AUTOSAR XML (schema 4-2-1)
package /VehicleProject
  system System
package /Diagnostics
  diagnostic service table DS_MyECU: diagnostic-connections=DC_0xE001_oMyECU_oCAN, ecu-instance=MyECU
  diagnostic connection DC_0xE001_oMyECU_oCAN: functional-request=msg_diag_RequestGlobal_oTN_0x00E0_Tester, physical-request=msg_diag_Request_MyECU_oTN_0x0001_MyECU, response=msg_diag_Response_MyECU_oTN_0x0001_MyECU
package /NM
  nm config NmConfig: can-nm-cluster-coupling=coupled-cluster=CAN
    can nm cluster CAN: communication-cluster=CAN, nm-channel-id=0, nm-cbv-position=0, nm-msg-cycle-time=0.1, nm-network-timeout=1, nm-nid-position=1, nm-repeat-message-time=0.4, nm-user-data-length=6, nm-wait-bus-sleep-time=0.75
      can nm node MyECU: controller=CT_CAN, nm-if-ecu=MyECU_CAN, nm-node-id=0, rx-nm-pdu=[msg_nm_OtherECU_oCAN, msg_nm_RearECU_oCAN], tx-nm-pdu=msg_nm_MyECU_oCAN, nm-msg-cycle-offset=0, nm-msg-reduced-time=0.05, nm-range-config={lower-can-id=1024, upper-can-id=1087}
      can nm node OtherECU: nm-if-ecu=OtherECU_CAN, nm-node-id=2, rx-nm-pdu=[msg_nm_MyECU_oCAN, msg_nm_RearECU_oCAN], tx-nm-pdu=msg_nm_OtherECU_oCAN, nm-msg-cycle-offset=0, nm-msg-reduced-time=0.05, nm-range-config={lower-can-id=1024, upper-can-id=1087}
      can nm node RearECU: nm-if-ecu=RearECU_CAN, nm-node-id=1, rx-nm-pdu=[msg_nm_MyECU_oCAN, msg_nm_OtherECU_oCAN], tx-nm-pdu=msg_nm_RearECU_oCAN, nm-msg-cycle-offset=0, nm-msg-reduced-time=0.05, nm-range-config={lower-can-id=1024, upper-can-id=1087}
    nm-if-ecus:
      nm ecu MyECU_CAN: ecu-instance=MyECU, nm-node-id-enabled=true, nm-user-data-enabled=true
      nm ecu OtherECU_CAN: nm-node-id-enabled=true, nm-user-data-enabled=true
      nm ecu RearECU_CAN: nm-node-id-enabled=true, nm-user-data-enabled=true
package /TP
  can tp config CAN: communication-cluster=CAN, can-tp-ecu{cycle-time-main-function=0.005, ecu-instance=MyECU}
    can tp address TA_0x0000: tp-address=0
    can tp address TA_0x0001: tp-address=1
    can tp address TA_0x00E0: tp-address=224
    can tp channel TPCH: channel-id=0, channel-mode=FULL-DUPLEX-MODE
    can-tp-connection addressing-format=STANDARD, can-tp-channel=TPCH, data-pdu=msg_diag_RequestGlobal_Tp_oCAN, multicast=TA_0x0000, receiver=TN_MyECU, ta-type=FUNCTIONAL, tp-sdu=msg_diag_RequestGlobal_oCAN, transmitter=TN_0x00E0_Tester:
      ident msg_diag_RequestGlobal_oTN_0x00E0_Tester
    can-tp-connection addressing-format=STANDARD, can-tp-channel=TPCH, data-pdu=msg_diag_Request_MyECU_Tp_oCAN, flow-control-pdu=msg_diag_Response_MyECU_Tp_oCAN, receiver=TN_0x0001_MyECU, ta-type=PHYSICAL, tp-sdu=msg_diag_Request_MyECU_oCAN, transmitter=TN_0x00E0_Tester:
      ident msg_diag_Request_MyECU_oTN_0x0001_MyECU
    can-tp-connection addressing-format=STANDARD, can-tp-channel=TPCH, data-pdu=msg_diag_Response_MyECU_Tp_oCAN, flow-control-pdu=msg_diag_Request_MyECU_Tp_oCAN, receiver=TN_0x00E0_Tester, ta-type=PHYSICAL, tp-sdu=msg_diag_Response_MyECU_oCAN, transmitter=TN_0x0001_MyECU:
      ident msg_diag_Response_MyECU_oTN_0x0001_MyECU
    can tp node TN_0x0001_MyECU: connector=CN_CAN, tp-address=TA_0x0001
    can tp node TN_0x00E0_Tester: tp-address=TA_0x00E0
    can tp node TN_MyECU: connector=CN_CAN
package /Cluster
  can cluster CAN: baudrate=500000, protocol-name=CAN
    can physical channel CHNL: comm-connectors=CN_CAN
      frame GlobalTimeMaster_oCAN: id 0x380, to MyECU, frame-length=8, can-addressing-mode=STANDARD
        user defined pdu GlobalTimeMaster_oCAN: length=8
      frame msg_diag_Request_MyECU_oCAN: id 0x610, to MyECU, frame-length=8, can-addressing-mode=STANDARD
        n pdu msg_diag_Request_MyECU_Tp_oCAN: length=8
      frame msg_diag_Request_MyECU_Slave3_oCAN: id 0x611, to MyECU, frame-length=8, can-addressing-mode=STANDARD
        user defined pdu msg_diag_Request_MyECU_Slave3_oCAN: length=8
      frame msg_diag_RequestGlobal_oCAN: id 0x614, to MyECU, frame-length=8, can-addressing-mode=STANDARD
        n pdu msg_diag_RequestGlobal_Tp_oCAN: length=8
      frame msg_diag_Response_MyECU_oCAN: id 0x612, from MyECU, frame-length=8, can-addressing-mode=STANDARD
        n pdu msg_diag_Response_MyECU_Tp_oCAN: length=8
      frame msg_diag_Response_MyECU_Slave3_oCAN: id 0x613, from MyECU, frame-length=8, can-addressing-mode=STANDARD
        user defined pdu msg_diag_Response_MyECU_Slave3_oCAN: length=8
      frame msg_diag_Uudt_Response_MyECU_oCAN: id 0x616, from MyECU, frame-length=8, can-addressing-mode=STANDARD
        dcm i pdu msg_diag_Uudt_Response_MyECU_oCAN: length=8, diag-pdu-type=DIAG-RESPONSE
      frame msg_nm_MyECU_oCAN: id 0x400, from MyECU, frame-length=8, can-addressing-mode=STANDARD
        nm pdu msg_nm_MyECU_oCAN: length=8, unused-bit-pattern=0
          signal NmUd_MyECU_16bit_omsg_nm_MyECU_oCAN: start 16, 16 bit, little-endian, init-value=0, base-type=uint16, compu-method=CM_NmUd_MyECU_16bit, transfer-property=PENDING
          signal NmUd_MyECU_32bit_omsg_nm_MyECU_oCAN: start 32, 32 bit, little-endian, init-value=0, base-type=uint32, compu-method=CM_NmUd_MyECU_32bit, transfer-property=PENDING
      frame msg_nm_OtherECU_oCAN: id 0x402, to MyECU, frame-length=8, can-addressing-mode=STANDARD
        nm pdu msg_nm_OtherECU_oCAN: length=8, unused-bit-pattern=0
      frame msg_nm_RearECU_oCAN: id 0x401, to MyECU, frame-length=8, can-addressing-mode=STANDARD
        nm pdu msg_nm_RearECU_oCAN: length=8, unused-bit-pattern=0
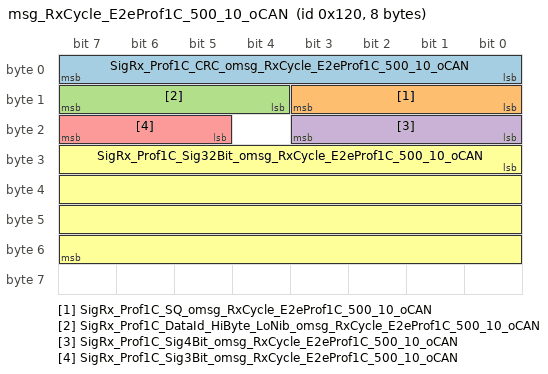
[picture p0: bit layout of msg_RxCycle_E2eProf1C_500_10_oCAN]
      frame msg_RxCycle_E2eProf1C_500_10_oCAN: id 0x120, to MyECU, frame-length=8, can-addressing-mode=STANDARD
        pdu msg_RxCycle_E2eProf1C_500_10_oCAN: length=8, minimum-delay=0, transmission-mode-false-timing=cyclic-timing={time-offset=0.01, time-period=0.5}, transmission-mode-true-timing=cyclic-timing={time-offset=0.01, time-period=0.5}, unused-bit-pattern=0
          signal SigRx_Prof1C_CRC_omsg_RxCycle_E2eProf1C_500_10_oCAN: start 0, 8 bit, little-endian, init-value=0, base-type=uint8, compu-method=CM_SigRx_Prof1C_CRC, transfer-property=PENDING, to MyECU
          signal SigRx_Prof1C_SQ_omsg_RxCycle_E2eProf1C_500_10_oCAN: start 8, 4 bit, little-endian, init-value=0, base-type=uint8, compu-method=CM_SigRx_Prof1C_SQ, transfer-property=PENDING, to MyECU
          signal SigRx_Prof1C_DataId_HiByte_LoNib_omsg_RxCycle_E2eProf1C_500_10_oCAN: start 12, 4 bit, little-endian, init-value=0, base-type=uint8, compu-method=CM_SigRx_Prof1C_DataId_HiByte_LoNib, transfer-property=PENDING, to MyECU
          signal SigRx_Prof1C_Sig4Bit_omsg_RxCycle_E2eProf1C_500_10_oCAN: start 16, 4 bit, little-endian, init-value=0, base-type=uint8, compu-method=CM_SigRx_Prof1C_Sig4Bit, transfer-property=PENDING, to MyECU
          signal SigRx_Prof1C_Sig3Bit_omsg_RxCycle_E2eProf1C_500_10_oCAN: start 21, 3 bit, little-endian, init-value=0, base-type=uint8, compu-method=CM_SigRx_Prof1C_Sig3Bit, transfer-property=PENDING, to MyECU
          signal SigRx_Prof1C_Sig32Bit_omsg_RxCycle_E2eProf1C_500_10_oCAN: start 24, 32 bit, little-endian, init-value=0, base-type=uint32, compu-method=CM_SigRx_Prof1C_Sig32Bit, transfer-property=PENDING, to MyECU
          mapping SG_RgRx_Prof1C_RxCycle: i-signal-group=SG_RgRx_Prof1C_RxCycle_omsg_RxCycle_E2eProf1C_500_10_oCAN, transfer-property=PENDING
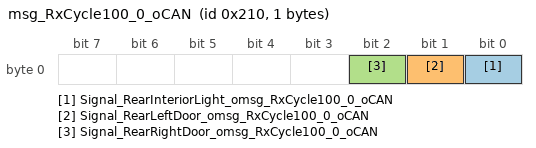
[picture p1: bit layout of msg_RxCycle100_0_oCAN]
      frame msg_RxCycle100_0_oCAN: id 0x210, to MyECU, frame-length=1, can-addressing-mode=STANDARD
        pdu msg_RxCycle100_0_oCAN: length=1, minimum-delay=0, transmission-mode-false-timing=cyclic-timing={time-offset=0, time-period=0.1}, transmission-mode-true-timing=cyclic-timing={time-offset=0, time-period=0.1}, unused-bit-pattern=0
          signal Signal_RearInteriorLight_omsg_RxCycle100_0_oCAN: start 0, 1 bit, little-endian, init-value=0, base-type=boolean, compu-method=CM_Signal_RearInteriorLight, transfer-property=PENDING, to MyECU
          signal Signal_RearLeftDoor_omsg_RxCycle100_0_oCAN: start 1, 1 bit, little-endian, init-value=0, base-type=boolean, compu-method=CM_Signal_RearLeftDoor, transfer-property=PENDING, to MyECU
          signal Signal_RearRightDoor_omsg_RxCycle100_0_oCAN: start 2, 1 bit, little-endian, init-value=0, base-type=boolean, compu-method=CM_Signal_RearRightDoor, transfer-property=PENDING, to MyECU
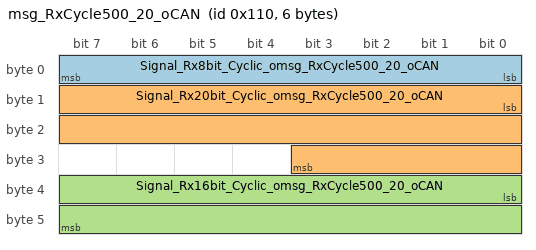
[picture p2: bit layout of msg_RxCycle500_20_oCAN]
      frame msg_RxCycle500_20_oCAN: id 0x110, to MyECU, frame-length=6, can-addressing-mode=STANDARD
        pdu msg_RxCycle500_20_oCAN: length=6, minimum-delay=0, transmission-mode-false-timing=cyclic-timing={time-offset=0.02, time-period=0.5}, transmission-mode-true-timing=cyclic-timing={time-offset=0.02, time-period=0.5}, unused-bit-pattern=0
          signal Signal_Rx8bit_Cyclic_omsg_RxCycle500_20_oCAN: start 0, 8 bit, little-endian, init-value=15, base-type=uint8, compu-method=CM_Signal_Rx8bit_Cyclic, transfer-property=PENDING, to MyECU
          signal Signal_Rx20bit_Cyclic_omsg_RxCycle500_20_oCAN: start 8, 20 bit, little-endian, init-value=1, base-type=uint32, compu-method=CM_Signal_Rx20bit_Cyclic, transfer-property=PENDING, to MyECU
          signal Signal_Rx16bit_Cyclic_omsg_RxCycle500_20_oCAN: start 32, 16 bit, little-endian, init-value=32768, base-type=uint16, compu-method=CM_Signal_Rx16bit_Cyclic, transfer-property=PENDING, to MyECU
      frame msg_RxEvent_20_oCAN: id 0x310, to MyECU, frame-length=4, can-addressing-mode=STANDARD
        pdu msg_RxEvent_20_oCAN: length=4, minimum-delay=0, transmission-mode-false-timing=event-controlled-timing={number-of-repetitions=0, repetition-period=0}, transmission-mode-true-timing=event-controlled-timing={number-of-repetitions=0, repetition-period=0}, unused-bit-pattern=0
          signal Signal_Rx11bit_OnWrite_omsg_RxEvent_20_oCAN: start 0, 11 bit, little-endian, init-value=50, base-type=uint16, compu-method=CM_Signal_Rx11bit_OnWrite, transfer-property=TRIGGERED-WITHOUT-REPETITION, to MyECU
          signal Signal_Rx15bit_OnWrite_omsg_RxEvent_20_oCAN: start 12, 15 bit, little-endian, init-value=25, base-type=uint16, compu-method=CM_Signal_Rx15bit_OnWrite, transfer-property=TRIGGERED-WITHOUT-REPETITION, to MyECU
      frame msg_StartAppl_Rx_MyECU_oCAN: id 0x501, to MyECU, frame-length=8, can-addressing-mode=STANDARD
        pdu msg_StartAppl_Rx_MyECU_oCAN: length=8, minimum-delay=0, transmission-mode-false-timing=cyclic-timing={time-offset=0, time-period=0.05}, transmission-mode-true-timing=cyclic-timing={time-offset=0, time-period=0.05}, unused-bit-pattern=0
          signal Signal_StartAppl_RxCtrl_MyECU_omsg_StartAppl_Rx_MyECU_oCAN: start 0, 8 bit, little-endian, init-value=0, base-type=uint8, compu-method=CM_Signal_StartAppl_RxCtrl_MyECU, transfer-property=PENDING, to MyECU
          signal Signal_StartAppl_RxData_MyECU_omsg_StartAppl_Rx_MyECU_oCAN: start 8, 8 bit, little-endian, init-value=0, base-type=uint8, compu-method=CM_Signal_StartAppl_RxData_MyECU, transfer-property=PENDING, to MyECU
      frame msg_StartAppl_Tx_MyECU_oCAN: id 0x500, from MyECU, frame-length=8, can-addressing-mode=STANDARD
        pdu msg_StartAppl_Tx_MyECU_oCAN: length=8, minimum-delay=0, transmission-mode-false-timing=cyclic-timing={time-offset=0, time-period=0.05}, transmission-mode-true-timing=cyclic-timing={time-offset=0, time-period=0.05}, unused-bit-pattern=0
          signal Signal_StartAppl_TxCtrl_MyECU_omsg_StartAppl_Tx_MyECU_oCAN: start 0, 8 bit, little-endian, init-value=0, base-type=uint8, compu-method=CM_Signal_StartAppl_TxCtrl_MyECU, transfer-property=PENDING
          signal Signal_StartAppl_TxData_MyECU_omsg_StartAppl_Tx_MyECU_oCAN: start 8, 8 bit, little-endian, init-value=0, base-type=uint8, compu-method=CM_Signal_StartAppl_TxData_MyECU, transfer-property=PENDING
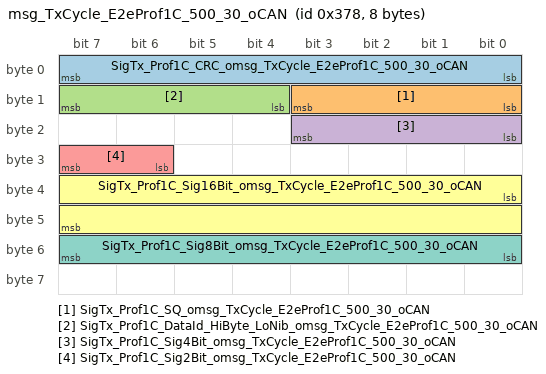
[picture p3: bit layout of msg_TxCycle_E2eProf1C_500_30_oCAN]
      frame msg_TxCycle_E2eProf1C_500_30_oCAN: id 0x378, from MyECU, frame-length=8, can-addressing-mode=STANDARD
        pdu msg_TxCycle_E2eProf1C_500_30_oCAN: length=8, minimum-delay=0, transmission-mode-false-timing=cyclic-timing={time-offset=0.03, time-period=0.5}, transmission-mode-true-timing=cyclic-timing={time-offset=0.03, time-period=0.5}, unused-bit-pattern=0
          signal SigTx_Prof1C_CRC_omsg_TxCycle_E2eProf1C_500_30_oCAN: start 0, 8 bit, little-endian, init-value=0, base-type=uint8, compu-method=CM_SigTx_Prof1C_CRC, transfer-property=PENDING
          signal SigTx_Prof1C_SQ_omsg_TxCycle_E2eProf1C_500_30_oCAN: start 8, 4 bit, little-endian, init-value=0, base-type=uint8, compu-method=CM_SigTx_Prof1C_SQ, transfer-property=PENDING
          signal SigTx_Prof1C_DataId_HiByte_LoNib_omsg_TxCycle_E2eProf1C_500_30_oCAN: start 12, 4 bit, little-endian, init-value=0, base-type=uint8, compu-method=CM_SigTx_Prof1C_DataId_HiByte_LoNib, transfer-property=PENDING
          signal SigTx_Prof1C_Sig4Bit_omsg_TxCycle_E2eProf1C_500_30_oCAN: start 16, 4 bit, little-endian, init-value=0, base-type=uint8, compu-method=CM_SigTx_Prof1C_Sig4Bit, transfer-property=PENDING
          signal SigTx_Prof1C_Sig2Bit_omsg_TxCycle_E2eProf1C_500_30_oCAN: start 30, 2 bit, little-endian, init-value=0, base-type=uint8, compu-method=CM_SigTx_Prof1C_Sig2Bit, transfer-property=PENDING
          signal SigTx_Prof1C_Sig16Bit_omsg_TxCycle_E2eProf1C_500_30_oCAN: start 32, 16 bit, little-endian, init-value=0, base-type=uint16, compu-method=CM_SigTx_Prof1C_Sig16Bit, transfer-property=PENDING
          signal SigTx_Prof1C_Sig8Bit_omsg_TxCycle_E2eProf1C_500_30_oCAN: start 48, 8 bit, little-endian, init-value=0, base-type=uint8, compu-method=CM_SigTx_Prof1C_Sig8Bit, transfer-property=PENDING
          mapping SG_SgTx_Prof1C_TxCycle: i-signal-group=SG_SgTx_Prof1C_TxCycle_omsg_TxCycle_E2eProf1C_500_30_oCAN, transfer-property=PENDING
      frame msg_TxCycle10_0_oCAN: id 0x268, from MyECU, frame-length=7, can-addressing-mode=STANDARD
        pdu msg_TxCycle10_0_oCAN: length=7, minimum-delay=0, transmission-mode-false-timing=cyclic-timing={time-offset=0, time-period=0.01}, transmission-mode-true-timing=cyclic-timing={time-offset=0, time-period=0.01}, unused-bit-pattern=0
          signal Signal_Tx32bit_Cyclic_omsg_TxCycle10_0_oCAN: start 0, 32 bit, little-endian, init-value=0, base-type=uint32, compu-method=CM_Signal_Tx32bit_Cyclic, transfer-property=PENDING
          signal Signal_Tx24bit_Cyclic_omsg_TxCycle10_0_oCAN: start 32, 24 bit, little-endian, init-value=0, base-type=uint32, compu-method=CM_Signal_Tx24bit_Cyclic, transfer-property=PENDING
      frame msg_TxCycle1000_10_oCAN: id 0x368, from MyECU, frame-length=2, can-addressing-mode=STANDARD
        pdu msg_TxCycle1000_10_oCAN: length=2, minimum-delay=0, transmission-mode-false-timing=cyclic-timing={time-offset=0.01, time-period=1}, transmission-mode-true-timing=cyclic-timing={time-offset=0.01, time-period=1}, unused-bit-pattern=0
          signal Signal_Tx10bit_Cyclic_omsg_TxCycle1000_10_oCAN: start 0, 10 bit, little-endian, init-value=0, base-type=uint16, compu-method=CM_Signal_Tx10bit_Cyclic, transfer-property=PENDING
          signal Signal_Tx4bit_Cyclic_omsg_TxCycle1000_10_oCAN: start 10, 4 bit, little-endian, init-value=0, base-type=uint8, compu-method=CM_Signal_Tx4bit_Cyclic, transfer-property=PENDING
      frame msg_TxEvent_10_oCAN: id 0x168, from MyECU, frame-length=7, can-addressing-mode=STANDARD
        pdu msg_TxEvent_10_oCAN: length=7, minimum-delay=0, transmission-mode-false-timing=event-controlled-timing={number-of-repetitions=0, repetition-period=0}, transmission-mode-true-timing=event-controlled-timing={number-of-repetitions=0, repetition-period=0}, unused-bit-pattern=0
          signal Signal_Tx32bit_OnWrite_omsg_TxEvent_10_oCAN: start 0, 32 bit, little-endian, init-value=31, base-type=uint32, compu-method=CM_Signal_Tx32bit_OnWrite, transfer-property=TRIGGERED-WITHOUT-REPETITION
          signal Signal_Tx24bit_OnWrite_omsg_TxEvent_10_oCAN: start 32, 24 bit, little-endian, init-value=63, base-type=uint32, compu-method=CM_Signal_Tx24bit_OnWrite, transfer-property=TRIGGERED-WITHOUT-REPETITION
      frame msg_XCP_Request_MyECU_oCAN: id 0x703, to MyECU, frame-length=8, can-addressing-mode=STANDARD
        xcp pdu msg_XCP_Request_MyECU_oCAN: length=8
      frame msg_XCP_Response_MyECU_oCAN: id 0x704, from MyECU, frame-length=8, can-addressing-mode=STANDARD
        xcp pdu msg_XCP_Response_MyECU_oCAN: length=8
      pdu triggering PT_msg_diag_Request_MyECU: pdu=msg_diag_Request_MyECU_oCAN, to MyECU
      pdu triggering PT_msg_diag_RequestGlobal: pdu=msg_diag_RequestGlobal_oCAN, to MyECU
      pdu triggering PT_msg_diag_Response_MyECU: pdu=msg_diag_Response_MyECU_oCAN, from MyECU
package /ECU
  ecu instance MyECU: associated-com-i-pdu-group=[MyECU_oCAN_Rx, MyECU_oCAN_Tx]
    can communication controller CT_CAN
    can communication connector CN_CAN: comm-controller=CT_CAN
package /IPDUGroup
  i signal i pdu group MyECU_oCAN_Rx: communication-direction=IN
    i-signal-i-pdus:
      msg_RxCycle_E2eProf1C_500_10_oCAN
      msg_RxCycle100_0_oCAN
      msg_RxCycle500_20_oCAN
      msg_RxEvent_20_oCAN
      msg_StartAppl_Rx_MyECU_oCAN
  i signal i pdu group MyECU_oCAN_Tx: communication-direction=OUT
    i-signal-i-pdus:
      msg_StartAppl_Tx_MyECU_oCAN
      msg_TxCycle_E2eProf1C_500_30_oCAN
      msg_TxCycle10_0_oCAN
      msg_TxCycle1000_10_oCAN
      msg_TxEvent_10_oCAN
package /PDU
  dcm i pdu msg_diag_Request_MyECU_oCAN: length=8, diag-pdu-type=DIAG-REQUEST
  dcm i pdu msg_diag_RequestGlobal_oCAN: length=7, diag-pdu-type=DIAG-REQUEST
  dcm i pdu msg_diag_Response_MyECU_oCAN: length=8, diag-pdu-type=DIAG-RESPONSE
package /ISignal
  i signal group SG_RgRx_Prof1C_RxCycle_omsg_RxCycle_E2eProf1C_500_10_oCAN: i-signal=[SigRx_Prof1C_CRC_omsg_RxCycle_E2eProf1C_500_10_oCAN, SigRx_Prof1C_DataId_HiByte_LoNib_omsg_RxCycle_E2eProf1C_500_10_oCAN, SigRx_Prof1C_Sig32Bit_omsg_RxCycle_E2eProf1C_500_10_oCAN, SigRx_Prof1C_Sig3Bit_omsg_RxCycle_E2eProf1C_500_10_oCAN, SigRx_Prof1C_Sig4Bit_omsg_RxCycle_E2eProf1C_500_10_oCAN, SigRx_Prof1C_SQ_omsg_RxCycle_E2eProf1C_500_10_oCAN], system-signal-group=SG_RgRx_Prof1C_RxCycle
  i signal group SG_SgTx_Prof1C_TxCycle_omsg_TxCycle_E2eProf1C_500_30_oCAN: i-signal=[SigTx_Prof1C_CRC_omsg_TxCycle_E2eProf1C_500_30_oCAN, SigTx_Prof1C_DataId_HiByte_LoNib_omsg_TxCycle_E2eProf1C_500_30_oCAN, SigTx_Prof1C_Sig16Bit_omsg_TxCycle_E2eProf1C_500_30_oCAN, SigTx_Prof1C_Sig2Bit_omsg_TxCycle_E2eProf1C_500_30_oCAN, SigTx_Prof1C_Sig4Bit_omsg_TxCycle_E2eProf1C_500_30_oCAN, SigTx_Prof1C_Sig8Bit_omsg_TxCycle_E2eProf1C_500_30_oCAN, SigTx_Prof1C_SQ_omsg_TxCycle_E2eProf1C_500_30_oCAN], system-signal-group=SG_SgTx_Prof1C_TxCycle
